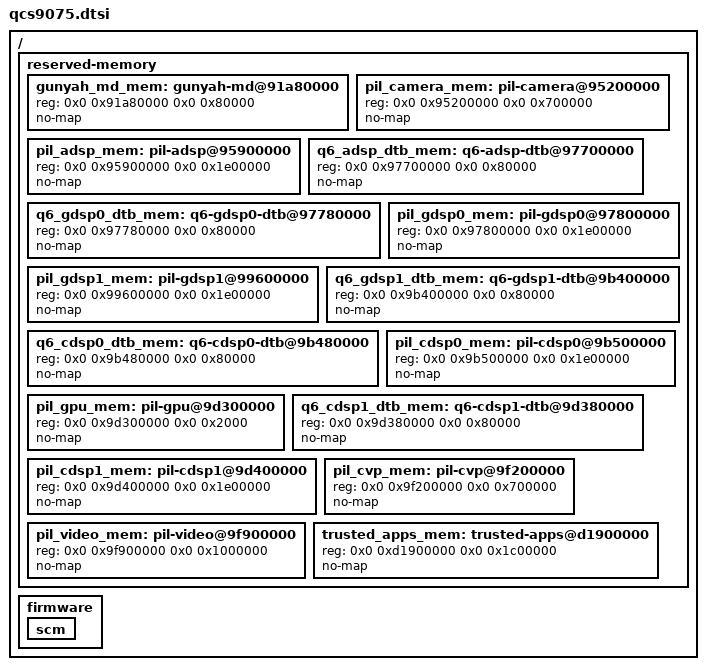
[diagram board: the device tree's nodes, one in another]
// SPDX-License-Identifier: BSD-3-Clause
/*
 * Copyright (c) 2025, Qualcomm Innovation Center, Inc. All rights reserved.
 */

/dts-v1/;

#include "sa8775p.dtsi"

/delete-node/ &pil_camera_mem;
/delete-node/ &pil_adsp_mem;
/delete-node/ &pil_gdsp0_mem;
/delete-node/ &pil_gdsp1_mem;
/delete-node/ &pil_cdsp0_mem;
/delete-node/ &pil_gpu_mem;
/delete-node/ &pil_cdsp1_mem;
/delete-node/ &pil_cvp_mem;
/delete-node/ &pil_video_mem;
/delete-node/ &audio_mdf_mem;
/delete-node/ &trusted_apps_mem;
/delete-node/ &hyptz_reserved_mem;
/delete-node/ &tz_ffi_mem;

/ {
	reserved-memory {
		#address-cells = <2>;
		#size-cells = <2>;
		ranges;

		gunyah_md_mem: gunyah-md@91a80000 {
			reg = <0x0 0x91a80000 0x0 0x80000>;
			no-map;
		};

		pil_camera_mem: pil-camera@95200000 {
			reg = <0x0 0x95200000 0x0 0x700000>;
			no-map;
		};

		pil_adsp_mem: pil-adsp@95900000 {
			reg = <0x0 0x95900000 0x0 0x1e00000>;
			no-map;
		};

		q6_adsp_dtb_mem: q6-adsp-dtb@97700000 {
			reg = <0x0 0x97700000 0x0 0x80000>;
			no-map;
		};

		q6_gdsp0_dtb_mem: q6-gdsp0-dtb@97780000 {
			reg = <0x0 0x97780000 0x0 0x80000>;
			no-map;
		};

		pil_gdsp0_mem: pil-gdsp0@97800000 {
			reg = <0x0 0x97800000 0x0 0x1e00000>;
			no-map;
		};

		pil_gdsp1_mem: pil-gdsp1@99600000 {
			reg = <0x0 0x99600000 0x0 0x1e00000>;
			no-map;
		};

		q6_gdsp1_dtb_mem: q6-gdsp1-dtb@9b400000 {
			reg = <0x0 0x9b400000 0x0 0x80000>;
			no-map;
		};

		q6_cdsp0_dtb_mem: q6-cdsp0-dtb@9b480000 {
			reg = <0x0 0x9b480000 0x0 0x80000>;
			no-map;
		};

		pil_cdsp0_mem: pil-cdsp0@9b500000 {
			reg = <0x0 0x9b500000 0x0 0x1e00000>;
			no-map;
		};

		pil_gpu_mem: pil-gpu@9d300000 {
			reg = <0x0 0x9d300000 0x0 0x2000>;
			no-map;
		};

		q6_cdsp1_dtb_mem: q6-cdsp1-dtb@9d380000 {
			reg = <0x0 0x9d380000 0x0 0x80000>;
			no-map;
		};

		pil_cdsp1_mem: pil-cdsp1@9d400000 {
			reg = <0x0 0x9d400000 0x0 0x1e00000>;
			no-map;
		};

		pil_cvp_mem: pil-cvp@9f200000 {
			reg = <0x0 0x9f200000 0x0 0x700000>;
			no-map;
		};

		pil_video_mem: pil-video@9f900000 {
			reg = <0x0 0x9f900000 0x0 0x1000000>;
			no-map;
		};

		trusted_apps_mem: trusted-apps@d1900000 {
			reg = <0x0 0xd1900000 0x0 0x1c00000>;
			no-map;
		};
	};

	firmware {
		scm {
			/delete-property/ memory-region;
		};
	};
};
